# ATSAMA5D35 register map
Vendor: Atmel; Series: SAMA5D3; File version: 20130221
Registers are 32-bit, read-write, reset 0x0 unless marked. A register's access mark holds for its fields unless they carry their own. Offsets are from the block's base; [hi:lo] are bit positions; {n}, {i} and the like mark numbered series.

## MPDDRC — AHB Multi-port DDR-SDRAM Controller
Base 0xFFFFEA00; register names take the prefix MPDDRC_
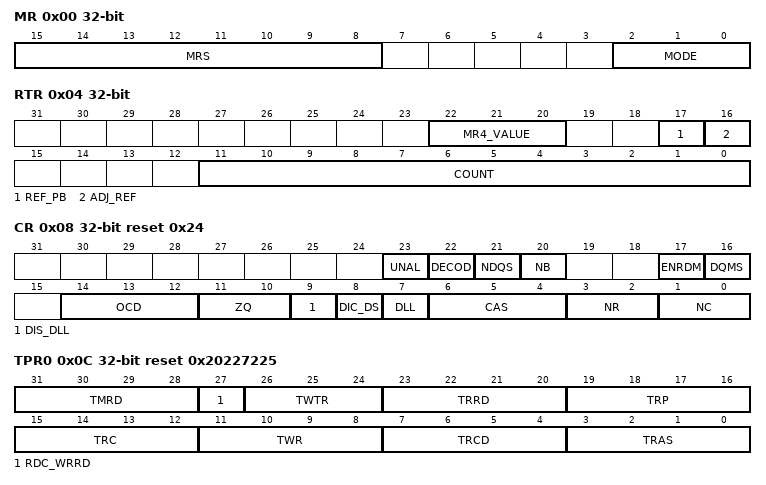
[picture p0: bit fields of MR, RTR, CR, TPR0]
0x00 MR — MPDDRC Mode Register
  [15:8] MRS — Mode Register Select LPDDR2
  [2:0] MODE — MPDDRC Command Mode
    0=NORMAL_CMD (Normal Mode. Any access to the MPDDRC will be decoded normally. To activate this mode, the command must be followed by a write to the DDR-SDRAM.); 1=NOP_CMD (The MPDDRC issues a NOP command when the DDR-SDRAM device is accessed regardless of the cycle. To activate this mode, the command must be followed by a write to the DDR-SDRAM.); 2=PRCGALL_CMD (The MPDDRC issues an "All Banks Precharge" command when the DDR-SDRAM device is accessed regardless of the cycle. To activate this mode, the command must be followed by a write to the SDRAM.); 3=LMR_CMD (The MPDDRC issues a "Load Mode Register" command when the DDR-SDRAM device is accessed regardless of the cycle. To activate this mode, the command must be followed by a write to the DDR-SDRAM.); 4=RFSH_CMD (The MPDDRC issues an "Auto-Refresh" Command when the DDR-SDRAM device is accessed regardless of the cycle. Previously, an "All Banks Precharge" command must be issued. To activate this mode, the command must be followed by a write to the DDR-SDRAM.); 5=EXT_LMR_CMD (The MPDDRC issues an "Extended Load Mode Register" command when the SDRAM device is accessed regardless of the cycle. To activate this mode, the command must be followed by a write to the DDR-SDRAM. The write in the DDR-SDRAM must be done in the appropriate bank.); 6=DEEP_CMD (Deep power mode: Access to deep power-down mode); 7=LPDDR2_CMD (The MPDDRC issues an "LPDDR2 Mode Register" command when the Low-power DDR2-SDRAM device is accessed regardless of the cycle. To activate this mode, the "Mode Register" command must be followed by a write to the Low-power DDR2-SDRAM.)
0x04 RTR — MPDDRC Refresh Timer Register
  [22:20] MR4_VALUE — Content of MR4 Register
  [17] REF_PB — Refresh Per Bank
  [16] ADJ_REF — Adjust Refresh Rate
  [11:0] COUNT — MPDDRC Refresh Timer Count
0x08 CR reset 0x24 — MPDDRC Configuration Register
  [23] UNAL — Support Unaligned Access
    0=UNSUPPORTED (Unaligned access is not supported.); 1=SUPPORTED (Unaligned access is supported.)
  [22] DECOD — Type of Decoding
  [21] NDQS — Not DQS:
    0=ENABLED (Not DQS is enabled.); 1=DISABLED (Not DQS is disabled.)
  [20] NB — Number of Banks.
    0=4 banks; 1=8 banks
  [17] ENRDM — Enable Read Measure
    0=OFF (DQS/DDR_DATA phase error correction is disabled.); 1=ON (DQS/DDR_DATA phase error correction is enabled.)
  [16] DQMS — Mask Data is Shared
    0=NOT_SHARED (DQM is not shared with another controller.); 1=SHARED (DQM is shared with another controller.)
  [14:12] OCD — Off-chip Driver
  [11:10] ZQ — ZQ Calibration
    0=INIT (Calibration command after initialization); 1=LONG (Long calibration); 2=SHORT (Short calibration); 3=RESET (ZQ Reset)
  [9] DIS_DLL — DISABLE DLL
  [8] DIC_DS — Output Driver Impedance Control (Drive Strength)
  [7] DLL — Reset DLL
    0=RESET_DISABLED (Disable DLL reset.); 1=RESET_ENABLED (Enable DLL reset.)
  [6:4] CAS — CAS Latency
    2=DDR_CAS2 (LPDDR1 CAS Latency 2); 3=DDR_CAS3 (DDR2/LPDDR2/LPDDR1 CAS Latency 3); 4=DDR_CAS4 (DDR2/LPDDR2 CAS Latency 4); 5=DDR_CAS5 (DDR2/LPDDR2 CAS Latency 5); 6=DDR_CAS6 (DDR2 CAS Latency 6)
  [3:2] NR — Number of Row Bits
    {v}=ROW_{v+11} ({v+11} row bits) (v=0..3)
  [1:0] NC — Number of Column Bits.
    {v}=COL_{v+9} ({v+9} DDR column bits) (v=0..3)
0x0C TPR0 reset 0x20227225 — MPDDRC Timing Parameter 0 Register
  [31:28] TMRD — Load Mode Register Command to Activate or Refresh Command
  [27] RDC_WRRD — Reduce Write to Read Delay
  [26:24] TWTR — Internal Write to Read Delay
  [23:20] TRRD — Active BankA to Active BankB
  [19:16] TRP — Row Precharge Delay
  [15:12] TRC — Row Cycle Delay
  [11:8] TWR — Write Recovery Delay
  [7:4] TRCD — Row to Column Delay
  [3:0] TRAS — Active to Precharge Delay
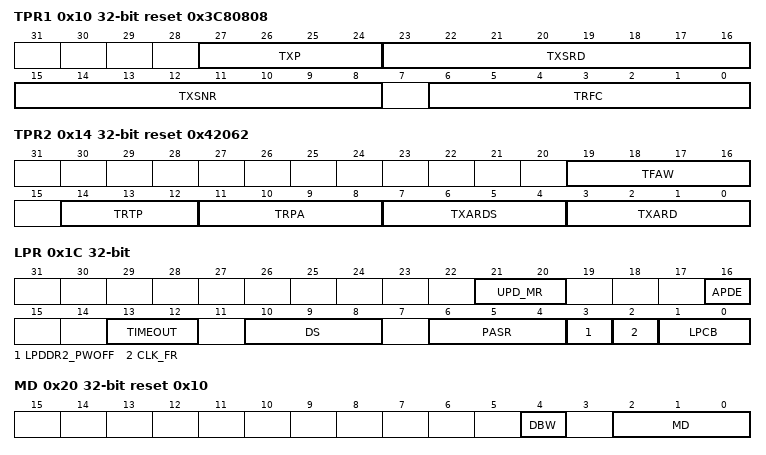
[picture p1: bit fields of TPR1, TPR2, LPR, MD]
0x10 TPR1 reset 0x3C80808 — MPDDRC Timing Parameter 1 Register
  [27:24] TXP — Exit Power-down Delay to First Command
  [23:16] TXSRD — Exit Self Refresh Delay to Read Command
  [15:8] TXSNR — Exit Self Refresh Delay to Non Read Command
  [6:0] TRFC — Row Cycle Delay
0x14 TPR2 reset 0x42062 — MPDDRC Timing Parameter 2 Register
  [19:16] TFAW — Four Active Windows
  [14:12] TRTP — Read to Precharge
  [11:8] TRPA — Row Precharge All Delay
  [7:4] TXARDS — Exit Active Power Down Delay to Read Command in Mode "Slow Exit".
  [3:0] TXARD — Exit Active Power Down Delay to Read Command in Mode "Fast Exit".
0x1C LPR — MPDDRC Low-power Register
  [21:20] UPD_MR — Update Load Mode Register and Extended Mode Register
    0=DISABLED (Update is disabled.)
  [16] APDE — Active Power Down Exit Time
    0=FAST (Fast Exit.); 1=SLOW (Low Exit.)
  [13:12] TIMEOUT — Enter Low-power Mode
    0=The SDRAM controller activates the SDRAM low-power mode immediately after the end of the last transfer; 1=The SDRAM controller activates the SDRAM low-power mode 64 clock cycles after the end of the last transfer; 2=The SDRAM controller activates the SDRAM low-power mode 128 clock cycles after the end of the last transfer
  [10:8] DS — Drive Strength
  [6:4] PASR — Partial Array Self Refresh
  [3] LPDDR2_PWOFF — LPDDR2 Power Off Bit
    0=DISABLED (No power off sequence applied to LPDDR2.); 1=ENABLED (A power off sequence is applied to the LPDDR2 device. CKE is forced low.)
  [2] CLK_FR — Clock Frozen Command Bit
    0=DISABLED (Clock(s) is/are not frozen.); 1=ENABLED (Clock(s) is/are frozen.)
  [1:0] LPCB — Low-power Command Bit
    0=DISABLED (Low-power Feature is inhibited. No power-down, self refresh and deep-power modes are issued to the DDR-SDRAM device.); 1=SELFREFRESH (The MPDDRC issues a Self Refresh command to the DDR-SDRAM device, the clock(s) is/are de-activated and the CKE signal is set low. The DDR-SDRAM device leaves the self refresh mode when accessed and reenters it after the access.); 2=POWERDOWN (The MPDDRC issues a Power-down Command to the DDR-SDRAM device after each access, the CKE signal is set low. The DDR-SDRAM device leaves the power-down mode when accessed and reenters it after the access.); 3=DEEP_PWD (The MPDDRC issues a Deep Power-down command to the Low-power DDR-SDRAM device.)
0x20 MD reset 0x10 — MPDDRC Memory Device Register
  [4] DBW — Data Bus Width
    0=DBW_32_BITS (Data bus width is 32 bits.); 1=DBW_16_BITS (Data bus width is 16 bits.(1))
  [2:0] MD — Memory Device
    3=LPDDR_SDRAM (Low-power DDR1-SDRAM); 6=DDR2_SDRAM; 7=LPDDR2_SDRAM (Low-Power DDR2-SDRAM)
0x24 HS — MPDDRC High Speed Register
  [2] DIS_ANTICIP_READ — Disable Anticip Read Access
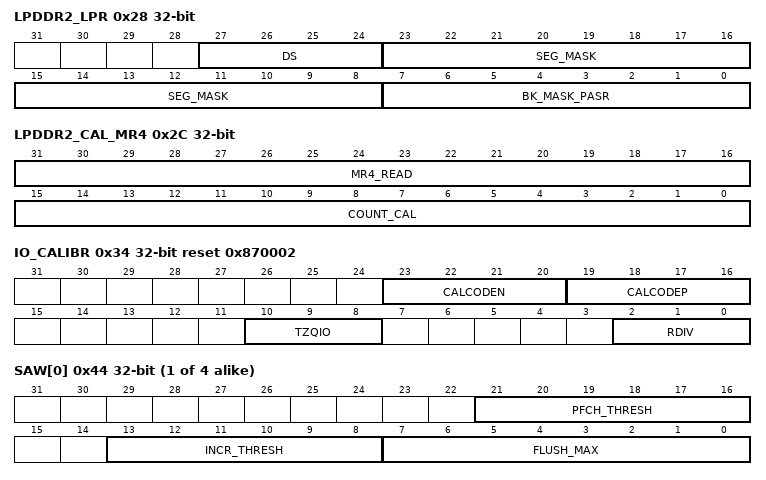
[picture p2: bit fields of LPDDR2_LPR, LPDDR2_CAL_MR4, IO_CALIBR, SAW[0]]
0x28 LPDDR2_LPR — MPDDRC LPDDR2 Low-power Register
  [27:24] DS — Drive strength
  [23:8] SEG_MASK — Segment Mask Bit
  [7:0] BK_MASK_PASR — Bank Mask Bit/PASR
0x2C LPDDR2_CAL_MR4 — MPDDRC LPDDR2 Calibration and MR4 Register
  [31:16] MR4_READ — Mode Register 4 Read Interval
  [15:0] COUNT_CAL — LPDDR2 Calibration Timer Count
0x30 LPDDR2_TIM_CAL reset 0x40 — MPDDRC LPDDR2 Timing Calibration Register
  [7:0] ZQCS — ZQ Calibration Short
0x34 IO_CALIBR reset 0x870002 — MPDDRC IO Calibration
  [23:20] CALCODEN — Number of Transistor N
  [19:16] CALCODEP — Number of Transistor P
  [10:8] TZQIO — IO Calibration
  [2:0] RDIV — Resistor Divider, output driver impedance
    1=RZQ_34 (LPDDR2 RZQ = 34,3 Ohm, DDR2/LPDDR1: Not applicable); 2=RZQ_40_RZQ_33_3 (LPDDR2:RZQ = 40 Ohm, DDR2/LPDDR1: RZQ = 33,3 Ohm); 3=RZQ_48_RZQ_40 (LPDDR2:RZQ =48 Ohm, DDR2/LPDDR1: RZQ =40 Ohm); 4=RZQ_60_RZQ_50 (LPDDR2:RZQ =60 Ohm, DDR2/LPDDR1: RZQ =50 Ohm); 6=RZQ_80_RZQ_66_7 (LPDDR2: RZQ = 80 Ohm, DDR2/LPDDR1: RZQ = 66,7 Ohm); 7=RZQ_120_RZQ_100 (LPDDR2:RZQ = 120 Ohm, DDR2/LPDDR1: RZQ = 100 Ohm)
{0x44+4i} SAW[{i}] (i=0..3) reset not defined — MPDDRC Smart Adaptation Wrapper 0 Register
  [21:16] PFCH_THRESH — Prefetch Threshold
    2=2 word/dword max; 4=4 word/dword max; 8=8 word/dword max
  [13:8] INCR_THRESH — Incremental Threshold
    1=1 word/dword max; 2=2 word/dword max; 4=4 word/dword max; 8=8 word/dword max; 16=16 word/dword max; 32=32 word/dword max
  [7:0] FLUSH_MAX — Clears FIFO Content
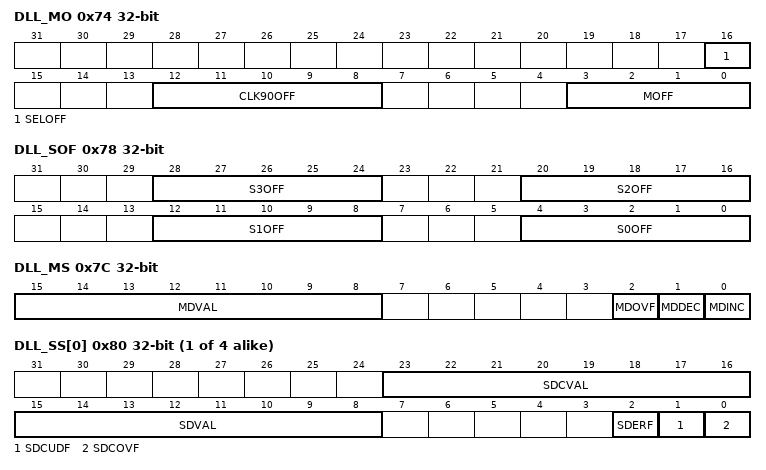
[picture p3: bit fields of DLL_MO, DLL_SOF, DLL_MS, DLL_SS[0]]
0x74 DLL_MO reset not defined — MPDDRC DLL Master Offset Register
  [16] SELOFF — DLL Offset Selection
  [12:8] CLK90OFF — DLL CLK90 Delay Line Offset
  [3:0] MOFF — DLL Master Delay Line Offset
0x78 DLL_SOF reset not defined — MPDDRC DLL Slave Offset Register
  [8n+4:8n] S{n}OFF (n=0..3) — DLL Slave {n} Delay Line Offset ([x=0..3])
0x7C DLL_MS ro — MPDDRC DLL Status Master Register
  [15:8] MDVAL — DLL Master Delay Value
  [2] MDOVF — DLL Master Delay Overflow Flag
  [1] MDDEC — DLL Master Delay Decrement
  [0] MDINC — DLL Master Delay Increment
{0x80+4i} DLL_SS[{i}] (i=0..3) ro reset not defined — MPDDRC DLL Status Slave 0 Register
  [23:16] SDCVAL — DLL Slave x Delay Correction Value
  [15:8] SDVAL — DLL Slave x Delay Value
  [2] SDERF — DLL Slave x Delay Correction Error Flag
  [1] SDCUDF — DLL Slave x Delay Correction Underflow Flag
  [0] SDCOVF — DLL Slave x Delay Correction Overflow Flag
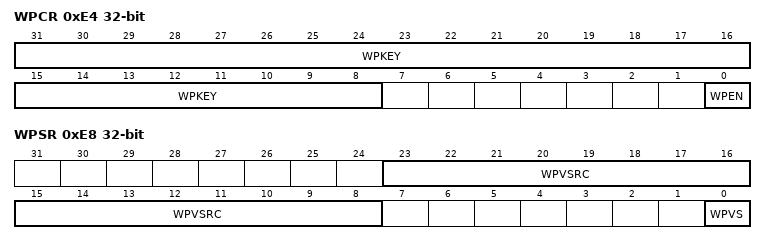
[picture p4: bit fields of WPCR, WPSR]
0xE4 WPCR — MPDDRC Write Protect Control Register
  [31:8] WPKEY — Write Protection KEY
  [0] WPEN — Write Protection Enable
0xE8 WPSR ro — MPDDRC Write Protect Status Register
  [23:8] WPVSRC — Write Protection Violation Source
  [0] WPVS — Write Protection Enable
